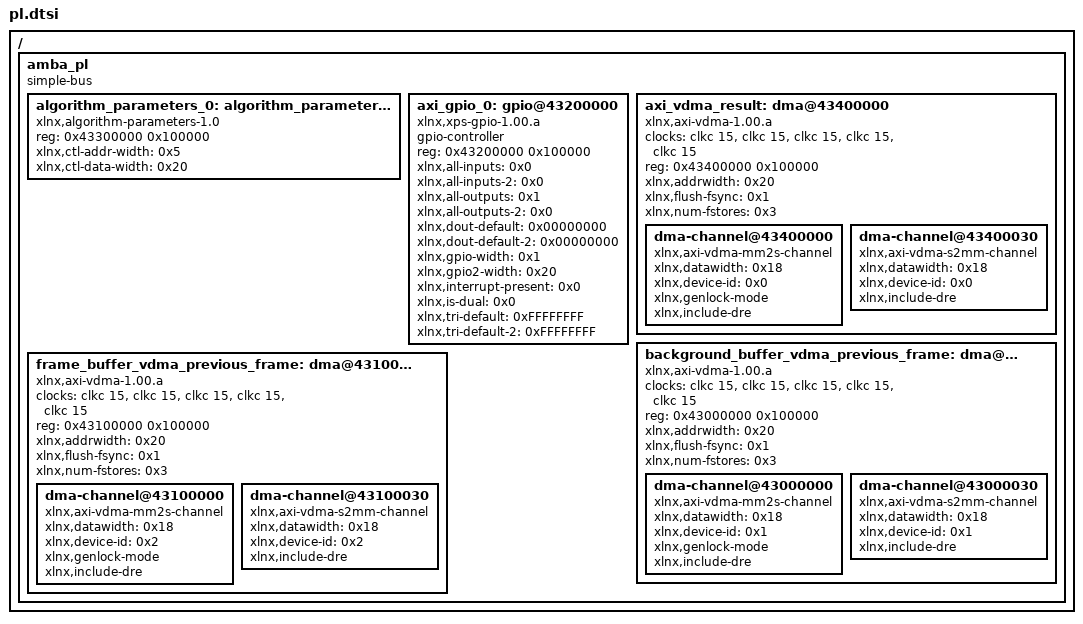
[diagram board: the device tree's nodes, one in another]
/*
 * CAUTION: This file is automatically generated by Xilinx.
 * Version: HSI 2016.3
 * Today is: Mon Sep  4 22:04:05 2017
*/


/ {
	amba_pl: amba_pl {
		#address-cells = <1>;
		#size-cells = <1>;
		compatible = "simple-bus";
		ranges ;
		algorithm_parameters_0: algorithm_parameters@43300000 {
			compatible = "xlnx,algorithm-parameters-1.0";
			reg = <0x43300000 0x100000>;
			xlnx,ctl-addr-width = <0x5>;
			xlnx,ctl-data-width = <0x20>;
		};
		axi_gpio_0: gpio@43200000 {
			#gpio-cells = <2>;
			compatible = "xlnx,xps-gpio-1.00.a";
			gpio-controller ;
			reg = <0x43200000 0x100000>;
			xlnx,all-inputs = <0x0>;
			xlnx,all-inputs-2 = <0x0>;
			xlnx,all-outputs = <0x1>;
			xlnx,all-outputs-2 = <0x0>;
			xlnx,dout-default = <0x00000000>;
			xlnx,dout-default-2 = <0x00000000>;
			xlnx,gpio-width = <0x1>;
			xlnx,gpio2-width = <0x20>;
			xlnx,interrupt-present = <0x0>;
			xlnx,is-dual = <0x0>;
			xlnx,tri-default = <0xFFFFFFFF>;
			xlnx,tri-default-2 = <0xFFFFFFFF>;
		};
		axi_vdma_result: dma@43400000 {
			#dma-cells = <1>;
			clock-names = "s_axi_lite_aclk", "m_axi_mm2s_aclk", "m_axi_mm2s_aclk", "m_axi_s2mm_aclk", "m_axi_s2mm_aclk";
			clocks = <&clkc 15>, <&clkc 15>, <&clkc 15>, <&clkc 15>, <&clkc 15>;
			compatible = "xlnx,axi-vdma-1.00.a";
			reg = <0x43400000 0x100000>;
			xlnx,addrwidth = <0x20>;
			xlnx,flush-fsync = <0x1>;
			xlnx,num-fstores = <0x3>;
			dma-channel@43400000 {
				compatible = "xlnx,axi-vdma-mm2s-channel";
				xlnx,datawidth = <0x18>;
				xlnx,device-id = <0x0>;
				xlnx,genlock-mode ;
				xlnx,include-dre ;
			};
			dma-channel@43400030 {
				compatible = "xlnx,axi-vdma-s2mm-channel";
				xlnx,datawidth = <0x18>;
				xlnx,device-id = <0x0>;
				xlnx,include-dre ;
			};
		};
		background_buffer_vdma_previous_frame: dma@43000000 {
			#dma-cells = <1>;
			clock-names = "s_axi_lite_aclk", "m_axi_mm2s_aclk", "m_axi_mm2s_aclk", "m_axi_s2mm_aclk", "m_axi_s2mm_aclk";
			clocks = <&clkc 15>, <&clkc 15>, <&clkc 15>, <&clkc 15>, <&clkc 15>;
			compatible = "xlnx,axi-vdma-1.00.a";
			reg = <0x43000000 0x100000>;
			xlnx,addrwidth = <0x20>;
			xlnx,flush-fsync = <0x1>;
			xlnx,num-fstores = <0x3>;
			dma-channel@43000000 {
				compatible = "xlnx,axi-vdma-mm2s-channel";
				xlnx,datawidth = <0x18>;
				xlnx,device-id = <0x1>;
				xlnx,genlock-mode ;
				xlnx,include-dre ;
			};
			dma-channel@43000030 {
				compatible = "xlnx,axi-vdma-s2mm-channel";
				xlnx,datawidth = <0x18>;
				xlnx,device-id = <0x1>;
				xlnx,include-dre ;
			};
		};
		frame_buffer_vdma_previous_frame: dma@43100000 {
			#dma-cells = <1>;
			clock-names = "s_axi_lite_aclk", "m_axi_mm2s_aclk", "m_axi_mm2s_aclk", "m_axi_s2mm_aclk", "m_axi_s2mm_aclk";
			clocks = <&clkc 15>, <&clkc 15>, <&clkc 15>, <&clkc 15>, <&clkc 15>;
			compatible = "xlnx,axi-vdma-1.00.a";
			reg = <0x43100000 0x100000>;
			xlnx,addrwidth = <0x20>;
			xlnx,flush-fsync = <0x1>;
			xlnx,num-fstores = <0x3>;
			dma-channel@43100000 {
				compatible = "xlnx,axi-vdma-mm2s-channel";
				xlnx,datawidth = <0x18>;
				xlnx,device-id = <0x2>;
				xlnx,genlock-mode ;
				xlnx,include-dre ;
			};
			dma-channel@43100030 {
				compatible = "xlnx,axi-vdma-s2mm-channel";
				xlnx,datawidth = <0x18>;
				xlnx,device-id = <0x2>;
				xlnx,include-dre ;
			};
		};
	};
};
